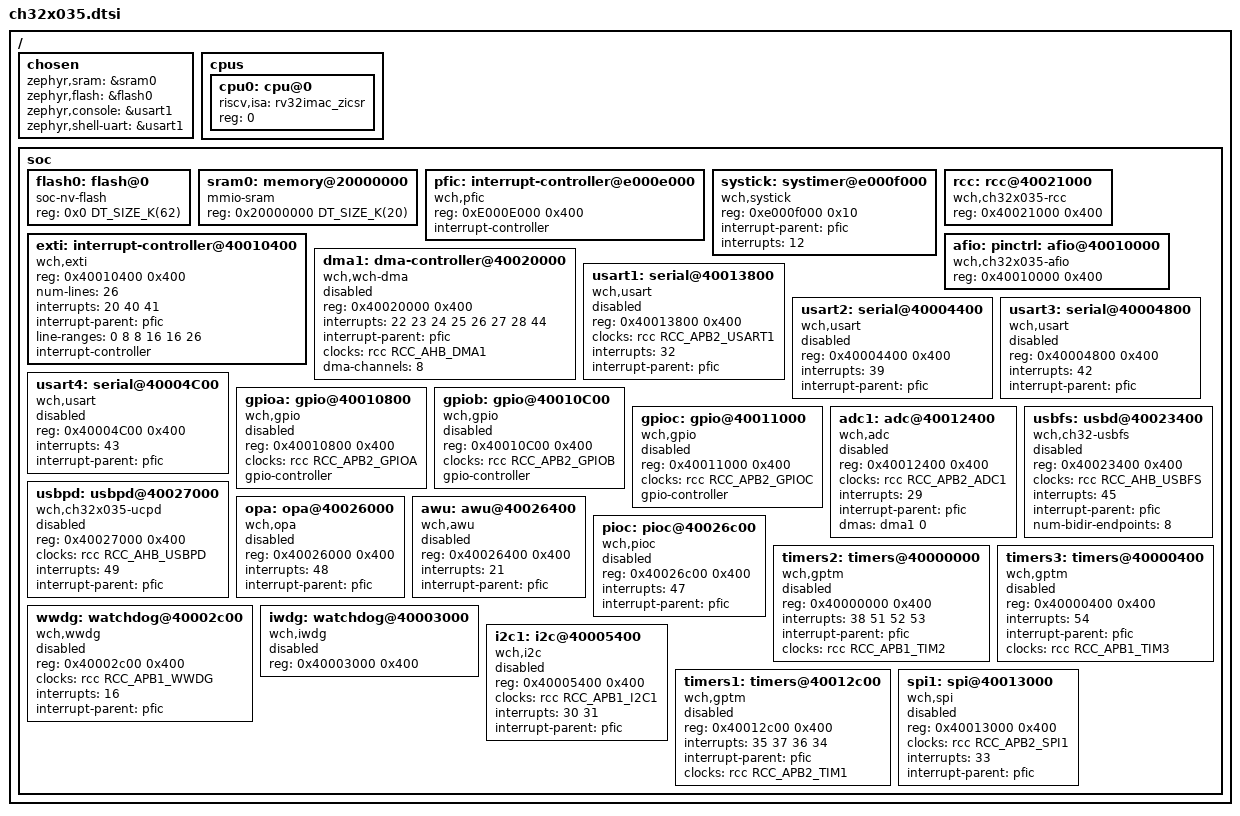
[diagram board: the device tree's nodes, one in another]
#include <mem.h>

#include <zephyr/dt-bindings/adc/ch32x035_adc.h>
#include <zephyr/dt-bindings/clock/ch32x035_clock.h>

/ {
	chosen {
		zephyr,sram = &sram0;
		zephyr,flash = &flash0;
		zephyr,console = &usart1;
		zephyr,shell-uart = &usart1;
	};

	cpus {
        #address-cells = <1>;
        #size-cells = <0>;

        cpu0: cpu@0 {
            device_type = "cpu";
            riscv,isa = "rv32imac_zicsr";
            reg = <0>;
        };
    };

    soc {
        #address-cells = <1>;
        #size-cells = <1>;

        flash0: flash@0 {
            compatible = "soc-nv-flash";
            reg = <0x0 DT_SIZE_K(62)>;
        };

        sram0: memory@20000000 {
            compatible = "mmio-sram";
            reg = <0x20000000 DT_SIZE_K(20)>;
        };

		pfic: interrupt-controller@e000e000 {
			compatible = "wch,pfic";
			reg = <0xE000E000 0x400>;
			interrupt-controller;
			#interrupt-cells = <1>;
			status = "okay";
		};

		systick: systimer@e000f000 {
			compatible = "wch,systick";
			reg = <0xe000f000 0x10>;
			status = "okay";
			interrupt-parent = <&pfic>;
			interrupts = <12>;
		};

        rcc: rcc@40021000 {
            compatible = "wch,ch32x035-rcc";
            reg = <0x40021000 0x400>;
            #clock-cells = <1>;
            status = "okay"; /* CH32X035 uses fixed 48MHz internal oscillator */
        };

        exti: interrupt-controller@40010400 {
            compatible = "wch,exti";
            reg = <0x40010400 0x400>;
            num-lines = <26>;
            interrupts = <20 40 41>;
            interrupt-parent = <&pfic>;
            interrupt-names = "exti0-7", "exti8-15", "exti16-25";
            line-ranges = <0 8 8 16 16 26>;
            interrupt-controller;
            #interrupt-cells = <1>;
            status = "okay";
        };

        afio: pinctrl: afio@40010000 {
            compatible = "wch,ch32x035-afio";
            reg = <0x40010000 0x400>;
            #address-cells = <1>;
            #size-cells = <1>;
            ranges;
            status = "okay";
        };

        dma1: dma-controller@40020000 {
            compatible = "wch,wch-dma";
            reg = <0x40020000 0x400>;
            interrupts = <22 23 24 25 26 27 28 44>; /* DMA1_Channel1..8 */
            interrupt-parent = <&pfic>;
            clocks = <&rcc RCC_AHB_DMA1>;
            dma-channels = <8>;
            #dma-cells = <1>;
            status = "disabled";
        };

        /*
         * Note: ch32x035-clock.h defines RCC_APB2Periph_USART1 etc.
         * The standard wch,rcc driver expects an index.
         * We need to verify if the header provides indices or bitmasks.
         * If bitmasks, we might need a custom rcc driver or adapter.
         * For now, assuming similar structure to other wch SoCs, 
         * or we might need to update the binding header.
         */

        usart1: serial@40013800 {
            compatible = "wch,usart";
            reg = <0x40013800 0x400>;
            clocks = <&rcc RCC_APB2_USART1>;
            interrupts = <32>;
            interrupt-parent = <&pfic>;
            status = "disabled";
        };

        usart2: serial@40004400 {
            compatible = "wch,usart";
            reg = <0x40004400 0x400>;
            interrupts = <39>;
            interrupt-parent = <&pfic>;
            status = "disabled";
        };

        usart3: serial@40004800 {
            compatible = "wch,usart";
            reg = <0x40004800 0x400>;
            interrupts = <42>;
            interrupt-parent = <&pfic>;
            status = "disabled";
        };

        usart4: serial@40004C00 {
            compatible = "wch,usart";
            reg = <0x40004C00 0x400>;
            interrupts = <43>;
            interrupt-parent = <&pfic>;
            status = "disabled";
        };

        gpioa: gpio@40010800 {
            compatible = "wch,gpio";
            reg = <0x40010800 0x400>;
            clocks = <&rcc RCC_APB2_GPIOA>;
            gpio-controller;
            #gpio-cells = <2>;
            status = "disabled";
        };

        gpiob: gpio@40010C00 {
            compatible = "wch,gpio";
            reg = <0x40010C00 0x400>;
            clocks = <&rcc RCC_APB2_GPIOB>;
            gpio-controller;
            #gpio-cells = <2>;
            status = "disabled";
        };

        gpioc: gpio@40011000 {
            compatible = "wch,gpio";
            reg = <0x40011000 0x400>;
            clocks = <&rcc RCC_APB2_GPIOC>;
            gpio-controller;
            #gpio-cells = <2>;
            status = "disabled";
        };

        adc1: adc@40012400 {
            compatible = "wch,adc";
            reg = <0x40012400 0x400>;
            clocks = <&rcc RCC_APB2_ADC1>;
            interrupts = <29>; // ADC1_IRQn
            interrupt-parent = <&pfic>;
            /* TouchKey channel is integrated in ADC1 */
            #address-cells = <1>;
            #size-cells = <0>;
            #io-channel-cells = <1>;
            dmas = <&dma1 0>;
            dma-names = "adc";
            status = "disabled";
        };

        usbfs: usbd@40023400 {
            compatible = "wch,ch32-usbfs";
            reg = <0x40023400 0x400>;
            clocks = <&rcc RCC_AHB_USBFS>;
            interrupts = <45>; // USBFS_IRQn
            interrupt-parent = <&pfic>;
            num-bidir-endpoints = <8>;
            status = "disabled";
        };

        usbpd: usbpd@40027000 {
            compatible = "wch,ch32x035-ucpd";
            reg = <0x40027000 0x400>;
            clocks = <&rcc RCC_AHB_USBPD>;
            interrupts = <49>; // USBPD_IRQn
            interrupt-parent = <&pfic>;
            status = "disabled";
        };

        opa: opa@40026000 {
            compatible = "wch,opa";
            reg = <0x40026000 0x400>;
            interrupts = <48>;
            interrupt-parent = <&pfic>;
            status = "disabled";
        };

        awu: awu@40026400 {
            compatible = "wch,awu";
            reg = <0x40026400 0x400>;
            interrupts = <21>;
            interrupt-parent = <&pfic>;
            status = "disabled";
        };

        pioc: pioc@40026c00 {
            compatible = "wch,pioc";
            reg = <0x40026c00 0x400>;
            interrupts = <47>;
            interrupt-parent = <&pfic>;
            status = "disabled";
        };
        timers2: timers@40000000 {
            compatible = "wch,gptm";
            reg = <0x40000000 0x400>;
            interrupts = <38 51 52 53>;
            interrupt-parent = <&pfic>;
            interrupt-names = "up", "cc", "trg_com", "brk";
            clocks = <&rcc RCC_APB1_TIM2>;
            status = "disabled";
        };

        timers3: timers@40000400 {
            compatible = "wch,gptm";
            reg = <0x40000400 0x400>;
            interrupts = <54>;
            interrupt-parent = <&pfic>;
            interrupt-names = "global";
            clocks = <&rcc RCC_APB1_TIM3>;
            status = "disabled";
        };

        wwdg: watchdog@40002c00 {
            compatible = "wch,wwdg";
            reg = <0x40002c00 0x400>;
            clocks = <&rcc RCC_APB1_WWDG>;
            interrupts = <16>;
            interrupt-parent = <&pfic>;
            status = "disabled";
        };

        iwdg: watchdog@40003000 {
            compatible = "wch,iwdg";
            reg = <0x40003000 0x400>;
            status = "disabled";
        };

        i2c1: i2c@40005400 {
            compatible = "wch,i2c";
            reg = <0x40005400 0x400>;
            clocks = <&rcc RCC_APB1_I2C1>;
            interrupts = <30 31>;
            interrupt-parent = <&pfic>;
            interrupt-names = "event", "error";
            status = "disabled";
        };

        timers1: timers@40012c00 {
            compatible = "wch,gptm"; /* Advanced timer, but typically compatible */
            reg = <0x40012c00 0x400>;
            interrupts = <35 37 36 34>;
            interrupt-parent = <&pfic>;
            interrupt-names = "up", "cc", "trg_com", "brk";
            clocks = <&rcc RCC_APB2_TIM1>;
            status = "disabled";
        };

        spi1: spi@40013000 {
            compatible = "wch,spi";
            reg = <0x40013000 0x400>;
            clocks = <&rcc RCC_APB2_SPI1>;
            interrupts = <33>;
            interrupt-parent = <&pfic>;
            status = "disabled";
        };
    };
};
